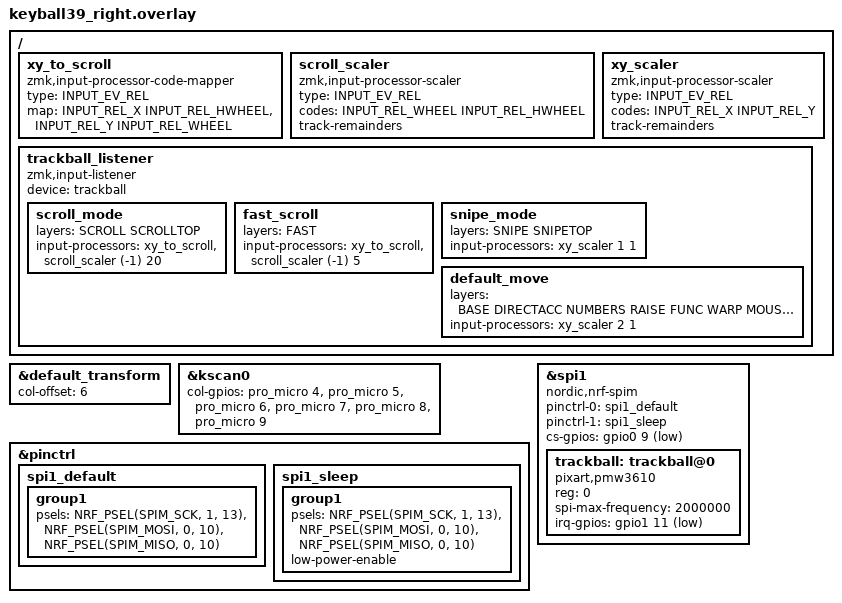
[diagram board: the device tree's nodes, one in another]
/*
 * Copyright (c) 2020 ZMK Contributors
 *
 * SPDX-License-Identifier: MIT
 */


#include "keyball39.dtsi"
#include <input/processors.dtsi>

&default_transform {
    col-offset = <6>;
};

&kscan0 {
	col-gpios
		= <&pro_micro 4 GPIO_ACTIVE_HIGH>
		, <&pro_micro 5 GPIO_ACTIVE_HIGH>
		, <&pro_micro 6 GPIO_ACTIVE_HIGH>
		, <&pro_micro 7 GPIO_ACTIVE_HIGH>
		, <&pro_micro 8 GPIO_ACTIVE_HIGH>
        , <&pro_micro 9 GPIO_ACTIVE_HIGH>
		;
};

&pinctrl {
    spi1_default: spi1_default {
        group1 {
            psels = <NRF_PSEL(SPIM_SCK, 1, 13)>,
                <NRF_PSEL(SPIM_MOSI, 0, 10)>,
                <NRF_PSEL(SPIM_MISO, 0, 10)>;
        };
    };

    spi1_sleep: spi1_sleep {
        group1 {
            psels = <NRF_PSEL(SPIM_SCK, 1, 13)>,
                <NRF_PSEL(SPIM_MOSI, 0, 10)>,
                <NRF_PSEL(SPIM_MISO, 0, 10)>;
            low-power-enable;
        };
    };
};

&spi1 {
    status = "okay";
    compatible = "nordic,nrf-spim";
    pinctrl-0 = <&spi1_default>;
    pinctrl-1 = <&spi1_sleep>;
    pinctrl-names = "default", "sleep";
    cs-gpios = <&gpio0 9 GPIO_ACTIVE_LOW>;

    trackball: trackball@0 {
        status = "okay";
        compatible = "pixart,pmw3610";
        reg = <0>;
        spi-max-frequency = <2000000>;
        irq-gpios = <&gpio1 11 (GPIO_ACTIVE_LOW | GPIO_PULL_UP)>;
    };
};

/ {
  /* Convert X/Y mouse movement to scroll wheel */
  xy_to_scroll: xy_to_scroll {
    compatible = "zmk,input-processor-code-mapper";
    #input-processor-cells = <0>;
    type = <INPUT_EV_REL>;
    map = <INPUT_REL_X INPUT_REL_HWHEEL>
        , <INPUT_REL_Y INPUT_REL_WHEEL>;
  };

  /* Scaler for scroll speed (negative multiplier inverts direction) */
  scroll_scaler: scroll_scaler {
    compatible = "zmk,input-processor-scaler";
    #input-processor-cells = <2>;
    type = <INPUT_EV_REL>;
    codes = <INPUT_REL_WHEEL INPUT_REL_HWHEEL>;
    track-remainders;
  };

  /* Scaler for mouse movement */
  xy_scaler: xy_scaler {
    compatible = "zmk,input-processor-scaler";
    #input-processor-cells = <2>;
    type = <INPUT_EV_REL>;
    codes = <INPUT_REL_X INPUT_REL_Y>;
    track-remainders;
  };
};

/ {
  trackball_listener {
    compatible = "zmk,input-listener";
    device = <&trackball>;

    /* Scroll layers - convert X/Y to scroll wheel (slower, inverted with -1) */
    scroll_mode {
        layers = <SCROLL SCROLLTOP>;
        input-processors = <&xy_to_scroll>, <&scroll_scaler (-1) 20>;
    };

    /* Fast scroll layer - faster than normal scroll (inverted with -1) */
    fast_scroll {
        layers = <FAST>;
        input-processors = <&xy_to_scroll>, <&scroll_scaler (-1) 5>;
    };

    /* Snipe mode - slower mouse */
    snipe_mode {
        layers = <SNIPE SNIPETOP>;
        input-processors = <&xy_scaler 1 1>;
    };

    /* Default mouse movement */
    default_move {
        layers = <BASE DIRECTACC NUMBERS RAISE FUNC WARP MOUSETOP>;
        input-processors = <&xy_scaler 2 1>;
    };

  };
};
